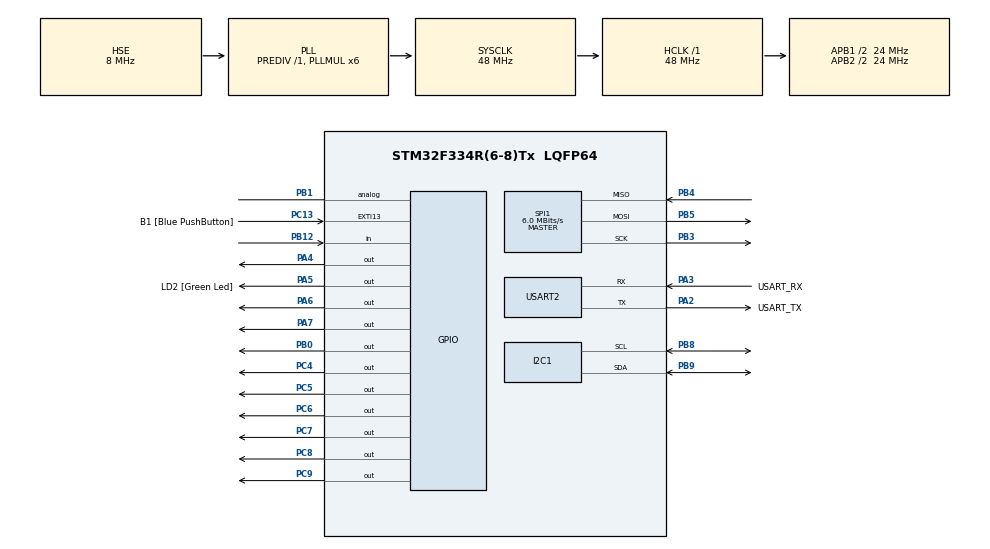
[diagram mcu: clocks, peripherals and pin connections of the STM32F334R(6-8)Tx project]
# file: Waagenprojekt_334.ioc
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Mcu.Family=STM32F3
Mcu.Name=STM32F334R(6-8)Tx
Mcu.Package=LQFP64
NVIC.PriorityGroup=NVIC_PRIORITYGROUP_0
PA13.GPIO_Label=TMS
PA13.Mode=Serial_Wire
PA13.Signal=SYS_JTMS-SWDIO
PA14.GPIO_Label=TCK
PA14.Mode=Serial_Wire
PA14.Signal=SYS_JTCK-SWCLK
PA2.GPIO_Label=USART_TX
PA2.Mode=Asynchronous
PA2.Signal=USART2_TX
PA3.GPIO_Label=USART_RX
PA3.Mode=Asynchronous
PA3.Signal=USART2_RX
PA4.Signal=GPIO_Output
PA5.GPIO_Label=LD2 [Green Led]
PA5.Signal=GPIO_Output
PA6.Signal=GPIO_Output
PA7.Signal=GPIO_Output
PB0.Signal=GPIO_Output
PB1.Signal=SharedAnalog_PB1
PB12.Signal=GPIO_Input
PB3.Mode=Full_Duplex_Master
PB3.Signal=SPI1_SCK
PB4.Mode=Full_Duplex_Master
PB4.Signal=SPI1_MISO
PB5.Mode=Full_Duplex_Master
PB5.Signal=SPI1_MOSI
PB8.Mode=I2C
PB8.Signal=I2C1_SCL
PB9.Mode=I2C
PB9.Signal=I2C1_SDA
PC13.GPIO_Label=B1 [Blue PushButton]
PC13.GPIO_ModeDefaultEXTI=GPIO_MODE_IT_FALLING
PC13.Signal=GPXTI13
PC14\ /\ OSC32_IN.Mode=LSE-External-Oscillator
PC14\ /\ OSC32_IN.Signal=RCC_OSC32_IN
PC15\ /\ OSC32_OUT.GPIO_Label=RCC_OSC32_OUT
PC15\ /\ OSC32_OUT.Mode=LSE-External-Oscillator
PC15\ /\ OSC32_OUT.Signal=RCC_OSC32_OUT
PC4.Signal=GPIO_Output
PC5.Signal=GPIO_Output
PC6.Signal=GPIO_Output
PC7.Signal=GPIO_Output
PC8.Signal=GPIO_Output
PC9.Signal=GPIO_Output
PF0\ /\ OSC_IN.Mode=HSE-External-Clock-Source
PF0\ /\ OSC_IN.Signal=RCC_OSC_IN
PF1\ /\ OSC_OUT.Signal=RCC_OSC_OUT
ProjectManager.HeapSize=0x200
ProjectManager.StackSize=0x400
ProjectManager.TargetToolchain=TrueSTUDIO
RCC.AHBFreq_Value=48000000
RCC.APB1CLKDivider=RCC_HCLK_DIV2
RCC.APB1Freq_Value=24000000
RCC.APB1TimFreq_Value=48000000
RCC.APB2CLKDivider=RCC_HCLK_DIV2
RCC.APB2Freq_Value=24000000
RCC.APB2TimFreq_Value=48000000
RCC.CortexFreq_Value=48000000
RCC.FLatency-AdvancedSettings=FLASH_LATENCY_1
RCC.HCLKFreq_Value=48000000
RCC.HSE_VALUE=8000000
RCC.HSI_VALUE=8000000
RCC.PLLMUL=RCC_PLL_MUL6
RCC.PLLSourceVirtual=RCC_PLLSOURCE_HSE
RCC.SYSCLKFreq_VALUE=48000000
RCC.SYSCLKSourceVirtual=RCC_SYSCLKSOURCE_PLLCLK
SH.SharedAnalog_PB1.0=ADC1_IN12
SH.SharedAnalog_PB1.1=GPIO_Analog
SPI1.BaudRatePrescaler=SPI_BAUDRATEPRESCALER_4
SPI1.CalculateBaudRate=6.0 MBits/s
SPI1.DataSize=SPI_DATASIZE_8BIT
SPI1.Direction=SPI_DIRECTION_2LINES
SPI1.Mode=SPI_MODE_MASTER
SPI1.VirtualType=VM_MASTER
USART2.VirtualMode-Asynchronous=VM_ASYNC
board=NUCLEO-F334R8

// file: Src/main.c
/**
  ******************************************************************************
  * @file           : main.c
  * @brief          : Main program body
  ******************************************************************************
  ** This notice applies to any and all portions of this file
  * that are not between comment pairs USER CODE BEGIN and
  * USER CODE END. Other portions of this file, whether
  * inserted by the user or by software development tools
  * are owned by their respective copyright owners.
  *
  * COPYRIGHT(c) 2018 STMicroelectronics
  *
  * Redistribution and use in source and binary forms, with or without modification,
  * are permitted provided that the following conditions are met:
  *   1. Redistributions of source code must retain the above copyright notice,
  *      this list of conditions and the following disclaimer.
  *   2. Redistributions in binary form must reproduce the above copyright notice,
  *      this list of conditions and the following disclaimer in the documentation
  *      and/or other materials provided with the distribution.
  *   3. Neither the name of STMicroelectronics nor the names of its contributors
  *      may be used to endorse or promote products derived from this software
  *      without specific prior written permission.
  *
  * THIS SOFTWARE IS PROVIDED BY THE COPYRIGHT HOLDERS AND CONTRIBUTORS "AS IS"
  * AND ANY EXPRESS OR IMPLIED WARRANTIES, INCLUDING, BUT NOT LIMITED TO, THE
  * IMPLIED WARRANTIES OF MERCHANTABILITY AND FITNESS FOR A PARTICULAR PURPOSE ARE
  * DISCLAIMED. IN NO EVENT SHALL THE COPYRIGHT HOLDER OR CONTRIBUTORS BE LIABLE
  * FOR ANY DIRECT, INDIRECT, INCIDENTAL, SPECIAL, EXEMPLARY, OR CONSEQUENTIAL
  * DAMAGES (INCLUDING, BUT NOT LIMITED TO, PROCUREMENT OF SUBSTITUTE GOODS OR
  * SERVICES; LOSS OF USE, DATA, OR PROFITS; OR BUSINESS INTERRUPTION) HOWEVER
  * CAUSED AND ON ANY THEORY OF LIABILITY, WHETHER IN CONTRACT, STRICT LIABILITY,
  * OR TORT (INCLUDING NEGLIGENCE OR OTHERWISE) ARISING IN ANY WAY OUT OF THE USE
  * OF THIS SOFTWARE, EVEN IF ADVISED OF THE POSSIBILITY OF SUCH DAMAGE.
  *
  ******************************************************************************
  */
#include "main.h"
#include "stm32f3xx_hal.h"
#include "i2c.h"
#include "spi.h"
#include "usart.h"
#include "gpio.h"

/* USER CODE BEGIN Includes */

#include "user_7segment.h"
#include "user_display.h"
#include "user_adafruit_adc.h"
#include "user_menu_guide.h"

#include "stm32f3xx_it.h"

/* USER CODE END Includes */

/* USER CODE BEGIN PV */
/* Private variables ---------------------------------------------------------*/

/* USER CODE END PV */

void SystemClock_Config(void);

/* USER CODE BEGIN PFP */
/* Private function prototypes -----------------------------------------------*/

/* USER CODE END PFP */

int main(void)
{
  /* USER CODE BEGIN 1 */
	volatile uint16_t mes_old = 0;
	volatile uint16_t mess_zero = 0;
	volatile uint16_t adc_result = 0;
	uint8_t first_messur = 0;
	char adc_value[5] = {0,0,0,0,0};
	extern user_systick this_systick;
	this_systick.test = 0;
  /* USER CODE END 1 */

  /* MCU Configuration----------------------------------------------------------*/

  /* Reset of all peripherals, Initializes the Flash interface and the Systick. */
  HAL_Init();

  /* Configure the system clock */
  SystemClock_Config();

  /* Initialize all configured peripherals */
  MX_GPIO_Init();
  MX_I2C1_Init();
  MX_SPI1_Init();
  MX_USART2_UART_Init();

  /* USER CODE BEGIN 2 */
  seg7_send_data("-----",0,0);

  HAL_Delay(5000);
  /* USER CODE END 2 */

  /* Infinite loop */
  while (1)
  {

	  switch(this_systick.test){
	  case 0:
		  seg7_send_data(adc_value,0,0);
		  break;
	  default:

		  mes_old = adc_result;

		  adc_result = Adafruit_ADS1115_SingleEnded(0);

		  adc_result = adc_result >> 2;

		  if(first_messur < 5){
			  mess_zero += adc_result;
			  mess_zero = mess_zero/first_messur;
			  first_messur++;
		  }

		  adc_result = (((adc_result - mess_zero) + (mes_old - mess_zero))/2);

		  sprintf(adc_value,"%05d",adc_result);

		  seg7_send_data(adc_value,0,0);

		  this_systick.test=0;
		  this_systick.adc=0;
		  break;
	  }

  }

}

void SystemClock_Config(void)
{

  RCC_OscInitTypeDef RCC_OscInitStruct;
  RCC_ClkInitTypeDef RCC_ClkInitStruct;
  RCC_PeriphCLKInitTypeDef PeriphClkInit;

    /**Initializes the CPU, AHB and APB busses clocks
    */
  RCC_OscInitStruct.OscillatorType = RCC_OSCILLATORTYPE_HSI|RCC_OSCILLATORTYPE_HSE;
  RCC_OscInitStruct.HSEState = RCC_HSE_BYPASS;
  RCC_OscInitStruct.HSEPredivValue = RCC_HSE_PREDIV_DIV1;
  RCC_OscInitStruct.HSIState = RCC_HSI_ON;
  RCC_OscInitStruct.HSICalibrationValue = 16;
  RCC_OscInitStruct.PLL.PLLState = RCC_PLL_ON;
  RCC_OscInitStruct.PLL.PLLSource = RCC_PLLSOURCE_HSE;
  RCC_OscInitStruct.PLL.PLLMUL = RCC_PLL_MUL6;
  if (HAL_RCC_OscConfig(&RCC_OscInitStruct) != HAL_OK)
  {
    _Error_Handler(__FILE__, __LINE__);
  }

    /**Initializes the CPU, AHB and APB busses clocks
    */
  RCC_ClkInitStruct.ClockType = RCC_CLOCKTYPE_HCLK|RCC_CLOCKTYPE_SYSCLK
                              |RCC_CLOCKTYPE_PCLK1|RCC_CLOCKTYPE_PCLK2;
  RCC_ClkInitStruct.SYSCLKSource = RCC_SYSCLKSOURCE_PLLCLK;
  RCC_ClkInitStruct.AHBCLKDivider = RCC_SYSCLK_DIV1;
  RCC_ClkInitStruct.APB1CLKDivider = RCC_HCLK_DIV2;
  RCC_ClkInitStruct.APB2CLKDivider = RCC_HCLK_DIV2;

  if (HAL_RCC_ClockConfig(&RCC_ClkInitStruct, FLASH_LATENCY_1) != HAL_OK)
  {
    _Error_Handler(__FILE__, __LINE__);
  }

  PeriphClkInit.PeriphClockSelection = RCC_PERIPHCLK_I2C1;
  PeriphClkInit.I2c1ClockSelection = RCC_I2C1CLKSOURCE_HSI;
  if (HAL_RCCEx_PeriphCLKConfig(&PeriphClkInit) != HAL_OK)
  {
    _Error_Handler(__FILE__, __LINE__);
  }

    /**Configure the Systick interrupt time
    */
  HAL_SYSTICK_Config(HAL_RCC_GetHCLKFreq()/1000);

    /**Configure the Systick
    */
  HAL_SYSTICK_CLKSourceConfig(SYSTICK_CLKSOURCE_HCLK);

  /* SysTick_IRQn interrupt configuration */
  HAL_NVIC_SetPriority(SysTick_IRQn, 0, 0);
}

void _Error_Handler(char *file, int line)
{
  while(1)
  {
  }
}

/************************ (C) COPYRIGHT STMicroelectronics *****END OF FILE****/
